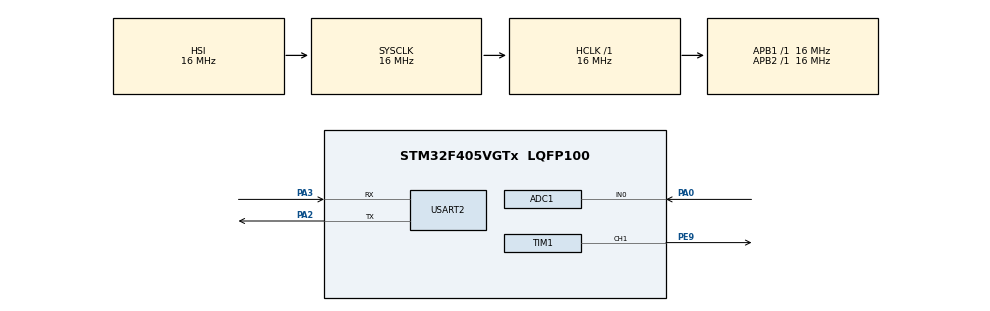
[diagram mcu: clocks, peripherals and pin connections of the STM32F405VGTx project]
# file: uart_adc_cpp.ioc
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ADC1.Channel-0\#ChannelRegularConversion=ADC_CHANNEL_0
ADC1.Channel-16\#ChannelInjectedConversion=ADC_CHANNEL_0
ADC1.Channel-17\#ChannelInjectedConversion=ADC_CHANNEL_0
ADC1.Channel-18\#ChannelInjectedConversion=ADC_CHANNEL_0
ADC1.Channel-19\#ChannelInjectedConversion=ADC_CHANNEL_0
ADC1.ContinuousConvMode=ENABLE
ADC1.DMAContinuousRequests=ENABLE
ADC1.EOCSelection=ADC_EOC_SEQ_CONV
ADC1.ExternalTrigInjecConv=ADC_EXTERNALTRIGINJECCONV_T1_TRGO
ADC1.InjNumberOfConversion=4
ADC1.InjectedOffset-16\#ChannelInjectedConversion=0
ADC1.InjectedOffset-17\#ChannelInjectedConversion=0
ADC1.InjectedOffset-18\#ChannelInjectedConversion=0
ADC1.InjectedOffset-19\#ChannelInjectedConversion=0
ADC1.InjectedRank-16\#ChannelInjectedConversion=1
ADC1.InjectedRank-17\#ChannelInjectedConversion=2
ADC1.InjectedRank-18\#ChannelInjectedConversion=3
ADC1.InjectedRank-19\#ChannelInjectedConversion=4
ADC1.NbrOfConversion=1
ADC1.NbrOfConversionFlag=1
ADC1.Rank-0\#ChannelRegularConversion=1
ADC1.Resolution=ADC_RESOLUTION_8B
ADC1.SamplingTime-0\#ChannelRegularConversion=ADC_SAMPLETIME_480CYCLES
ADC1.SamplingTime-16\#ChannelInjectedConversion=ADC_SAMPLETIME_3CYCLES
ADC1.SamplingTime-17\#ChannelInjectedConversion=ADC_SAMPLETIME_3CYCLES
ADC1.SamplingTime-18\#ChannelInjectedConversion=ADC_SAMPLETIME_3CYCLES
ADC1.SamplingTime-19\#ChannelInjectedConversion=ADC_SAMPLETIME_3CYCLES
ADC1.master=1
Dma.ADC1.1.Direction=DMA_PERIPH_TO_MEMORY
Dma.ADC1.1.FIFOMode=DMA_FIFOMODE_DISABLE
Dma.ADC1.1.Instance=DMA2_Stream0
Dma.ADC1.1.MemDataAlignment=DMA_MDATAALIGN_HALFWORD
Dma.ADC1.1.MemInc=DMA_MINC_ENABLE
Dma.ADC1.1.Mode=DMA_NORMAL
Dma.ADC1.1.PeriphDataAlignment=DMA_PDATAALIGN_HALFWORD
Dma.ADC1.1.PeriphInc=DMA_PINC_DISABLE
Dma.ADC1.1.Priority=DMA_PRIORITY_LOW
Dma.Request0=USART2_TX
Dma.Request1=ADC1
Dma.USART2_TX.0.Direction=DMA_MEMORY_TO_PERIPH
Dma.USART2_TX.0.FIFOMode=DMA_FIFOMODE_DISABLE
Dma.USART2_TX.0.Instance=DMA1_Stream6
Dma.USART2_TX.0.MemDataAlignment=DMA_MDATAALIGN_BYTE
Dma.USART2_TX.0.MemInc=DMA_MINC_ENABLE
Dma.USART2_TX.0.Mode=DMA_NORMAL
Dma.USART2_TX.0.PeriphDataAlignment=DMA_PDATAALIGN_BYTE
Dma.USART2_TX.0.PeriphInc=DMA_PINC_DISABLE
Dma.USART2_TX.0.Priority=DMA_PRIORITY_LOW
Mcu.Family=STM32F4
Mcu.Name=STM32F405VGTx
Mcu.Package=LQFP100
NVIC.DMA1_Stream6_IRQn=true\:0\:0\:false\:false\:true\:false
NVIC.DMA2_Stream0_IRQn=true\:0\:0\:false\:false\:true\:false
NVIC.PriorityGroup=NVIC_PRIORITYGROUP_4
PA0-WKUP.Signal=ADCx_IN0
PA2.Mode=Asynchronous
PA2.Signal=USART2_TX
PA3.Mode=Asynchronous
PA3.Signal=USART2_RX
PC14-OSC32_IN.Mode=LSE-External-Oscillator
PC14-OSC32_IN.Signal=RCC_OSC32_IN
PC15-OSC32_OUT.Mode=LSE-External-Oscillator
PC15-OSC32_OUT.Signal=RCC_OSC32_OUT
PE9.Signal=S_TIM1_CH1
PH0-OSC_IN.Mode=HSE-External-Oscillator
PH0-OSC_IN.Signal=RCC_OSC_IN
PH1-OSC_OUT.Mode=HSE-External-Oscillator
PH1-OSC_OUT.Signal=RCC_OSC_OUT
ProjectManager.HeapSize=0x200
ProjectManager.StackSize=0x400
ProjectManager.TargetToolchain=SW4STM32
RCC.AHBFreq_Value=16000000
RCC.APB1Freq_Value=16000000
RCC.APB2Freq_Value=16000000
RCC.CortexFreq_Value=16000000
RCC.HSE_VALUE=25000000
RCC.HSI_VALUE=16000000
RCC.SYSCLKFreq_VALUE=16000000
RCC.VCOOutputFreq_Value=192000000
SH.ADCx_IN0.0=ADC1_IN0,IN0
SH.S_TIM1_CH1.0=TIM1_CH1,Output Compare1 CH1
TIM1.Channel-Output\ Compare1\ CH1=TIM_CHANNEL_1
TIM1.Period=1000-1
TIM1.Prescaler=7200-1
TIM1.TIM_MasterOutputTrigger=TIM_TRGO_UPDATE
USART2.VirtualMode=VM_ASYNC
VP_TIM1_VS_ClockSourceITR.Mode=TriggerSource_ITR0
VP_TIM1_VS_ControllerModeClock.Mode=Clock Mode
board=custom

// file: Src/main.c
/* USER CODE BEGIN Header */
/**
 ******************************************************************************
 * @file           : main.c
 * @brief          : Main program body
 ******************************************************************************
 ** This notice applies to any and all portions of this file
 * that are not between comment pairs USER CODE BEGIN and
 * USER CODE END. Other portions of this file, whether
 * inserted by the user or by software development tools
 * are owned by their respective copyright owners.
 *
 * COPYRIGHT(c) 2019 STMicroelectronics
 *
 * Redistribution and use in source and binary forms, with or without modification,
 * are permitted provided that the following conditions are met:
 *   1. Redistributions of source code must retain the above copyright notice,
 *      this list of conditions and the following disclaimer.
 *   2. Redistributions in binary form must reproduce the above copyright notice,
 *      this list of conditions and the following disclaimer in the documentation
 *      and/or other materials provided with the distribution.
 *   3. Neither the name of STMicroelectronics nor the names of its contributors
 *      may be used to endorse or promote products derived from this software
 *      without specific prior written permission.
 *
 * THIS SOFTWARE IS PROVIDED BY THE COPYRIGHT HOLDERS AND CONTRIBUTORS "AS IS"
 * AND ANY EXPRESS OR IMPLIED WARRANTIES, INCLUDING, BUT NOT LIMITED TO, THE
 * IMPLIED WARRANTIES OF MERCHANTABILITY AND FITNESS FOR A PARTICULAR PURPOSE ARE
 * DISCLAIMED. IN NO EVENT SHALL THE COPYRIGHT HOLDER OR CONTRIBUTORS BE LIABLE
 * FOR ANY DIRECT, INDIRECT, INCIDENTAL, SPECIAL, EXEMPLARY, OR CONSEQUENTIAL
 * DAMAGES (INCLUDING, BUT NOT LIMITED TO, PROCUREMENT OF SUBSTITUTE GOODS OR
 * SERVICES; LOSS OF USE, DATA, OR PROFITS; OR BUSINESS INTERRUPTION) HOWEVER
 * CAUSED AND ON ANY THEORY OF LIABILITY, WHETHER IN CONTRACT, STRICT LIABILITY,
 * OR TORT (INCLUDING NEGLIGENCE OR OTHERWISE) ARISING IN ANY WAY OUT OF THE USE
 * OF THIS SOFTWARE, EVEN IF ADVISED OF THE POSSIBILITY OF SUCH DAMAGE.
 *
 ******************************************************************************
 */
/* USER CODE END Header */

#include "main.h"

ADC_HandleTypeDef hadc1;
DMA_HandleTypeDef hdma_adc1;

TIM_HandleTypeDef htim1;

UART_HandleTypeDef huart2;
DMA_HandleTypeDef hdma_usart2_tx;

void SystemClock_Config(void);
static void MX_GPIO_Init(void);
static void MX_DMA_Init(void);
static void MX_ADC1_Init(void);
static void MX_USART2_UART_Init(void);
static void MX_TIM1_Init(void);
/* USER CODE BEGIN PFP */

uint8_t data; //signed short pour avoir une précision suffisante pour l'affichage
float data_convertit;// une fois la valeur convertit le short et inutil
/* USER CODE END PFP */

int main(void)
{

  /* MCU Configuration--------------------------------------------------------*/

  /* Reset of all peripherals, Initializes the Flash interface and the Systick. */
  HAL_Init();

  /* Configure the system clock */
  SystemClock_Config();

  /* Initialize all configured peripherals */
  MX_GPIO_Init();
  MX_DMA_Init();
  MX_ADC1_Init();
  MX_USART2_UART_Init();
  MX_TIM1_Init();

  /* Infinite loop */
  /* USER CODE BEGIN WHILE */
	HAL_UART_Transmit(&huart2,(uint8_t*)"\033c",6,10); //reintialise la vision du  terminal à chaque reset
	//HAL_ADC_Start (&hadc1);//demarrage de l'adc
	HAL_TIM_Base_Start_IT(&htim1);
	while (1)
	{
		//conversion en continue
		HAL_ADC_Start (&hadc1);//demarrag adc
		HAL_ADC_PollForConversion(&hadc1,1000);//initialisation adc en reglant lequel ADC et combien de timout
		data = HAL_ADC_GetValue(&hadc1);//récuperation de valeur
		data_convertit =(float) (((3.3)* data)/(256-1));//conversion de la valeur en tension
		HAL_UART_Transmit(&huart2,(&data_convertit),1,10);//envoie de la valeur
		HAL_ADC_Stop (&hadc1);

		HAL_Delay(10);
		/*if(HAL_ADC_PollForConversion(&hadc1,1000000) == HAL_OK)//
		{
			data = HAL_ADC_GetValue(&hadc1);//cast int vers char pour le stockage de la donnée reçue en caractere

			//permet la conversion de la valeur en tension pour l'affiché est l'afficher directement sur l'afficheur cpp

			if(data<0)
				data_convertit = (((-3)*data)/-32768);//on prend la valeur min en tension on la multiplie par la valeur a convertir on la divise par la valeur min en signé
			else if (data > 0)
				data_convertit = (((3)*data)/32767);//on prend la valeur max en tension on la multiplie par la valeur a convertir on la divise par la valeur max en signé
			else if (data == 0 )
				data_convertit=0;//si la valeur est 0 la conversion est inutile
			HAL_UART_Transmit(&huart2,(&data_convertit),8,100);
		}*/
		//envoie de 8 octet pour la transmission d'un double ,
		//generation d'un warning car j'envoie un double au lieu d'un unsigned char
		//mais si je realise ce cast la valeur ne conviendra plus

		data = 0;//reinitialisation de la valeur
	}
    /* USER CODE END WHILE */

}

void SystemClock_Config(void)
{
  RCC_OscInitTypeDef RCC_OscInitStruct = {0};
  RCC_ClkInitTypeDef RCC_ClkInitStruct = {0};

  /**Configure the main internal regulator output voltage
  */
  __HAL_RCC_PWR_CLK_ENABLE();
  __HAL_PWR_VOLTAGESCALING_CONFIG(PWR_REGULATOR_VOLTAGE_SCALE1);
  /**Initializes the CPU, AHB and APB busses clocks
  */
  RCC_OscInitStruct.OscillatorType = RCC_OSCILLATORTYPE_HSI;
  RCC_OscInitStruct.HSIState = RCC_HSI_ON;
  RCC_OscInitStruct.HSICalibrationValue = RCC_HSICALIBRATION_DEFAULT;
  RCC_OscInitStruct.PLL.PLLState = RCC_PLL_NONE;
  if (HAL_RCC_OscConfig(&RCC_OscInitStruct) != HAL_OK)
  {
    Error_Handler();
  }
  /**Initializes the CPU, AHB and APB busses clocks
  */
  RCC_ClkInitStruct.ClockType = RCC_CLOCKTYPE_HCLK|RCC_CLOCKTYPE_SYSCLK
                              |RCC_CLOCKTYPE_PCLK1|RCC_CLOCKTYPE_PCLK2;
  RCC_ClkInitStruct.SYSCLKSource = RCC_SYSCLKSOURCE_HSI;
  RCC_ClkInitStruct.AHBCLKDivider = RCC_SYSCLK_DIV1;
  RCC_ClkInitStruct.APB1CLKDivider = RCC_HCLK_DIV1;
  RCC_ClkInitStruct.APB2CLKDivider = RCC_HCLK_DIV1;

  if (HAL_RCC_ClockConfig(&RCC_ClkInitStruct, FLASH_LATENCY_0) != HAL_OK)
  {
    Error_Handler();
  }
}

static void MX_ADC1_Init(void)
{

  ADC_ChannelConfTypeDef sConfig = {0};
  ADC_InjectionConfTypeDef sConfigInjected = {0};

  /**Configure the global features of the ADC (Clock, Resolution, Data Alignment and number of conversion)
  */
  hadc1.Instance = ADC1;
  hadc1.Init.ClockPrescaler = ADC_CLOCK_SYNC_PCLK_DIV2;
  hadc1.Init.Resolution = ADC_RESOLUTION_8B;
  hadc1.Init.ScanConvMode = ENABLE;
  hadc1.Init.ContinuousConvMode = ENABLE;
  hadc1.Init.DiscontinuousConvMode = DISABLE;
  hadc1.Init.ExternalTrigConvEdge = ADC_EXTERNALTRIGCONVEDGE_NONE;
  hadc1.Init.ExternalTrigConv = ADC_SOFTWARE_START;
  hadc1.Init.DataAlign = ADC_DATAALIGN_RIGHT;
  hadc1.Init.NbrOfConversion = 1;
  hadc1.Init.DMAContinuousRequests = ENABLE;
  hadc1.Init.EOCSelection = ADC_EOC_SEQ_CONV;
  if (HAL_ADC_Init(&hadc1) != HAL_OK)
  {
    Error_Handler();
  }
  /**Configure for the selected ADC regular channel its corresponding rank in the sequencer and its sample time.
  */
  sConfig.Channel = ADC_CHANNEL_0;
  sConfig.Rank = 1;
  sConfig.SamplingTime = ADC_SAMPLETIME_480CYCLES;
  if (HAL_ADC_ConfigChannel(&hadc1, &sConfig) != HAL_OK)
  {
    Error_Handler();
  }
  /**Configures for the selected ADC injected channel its corresponding rank in the sequencer and its sample time
  */
  sConfigInjected.InjectedChannel = ADC_CHANNEL_0;
  sConfigInjected.InjectedRank = 1;
  sConfigInjected.InjectedNbrOfConversion = 4;
  sConfigInjected.InjectedSamplingTime = ADC_SAMPLETIME_3CYCLES;
  sConfigInjected.ExternalTrigInjecConvEdge = ADC_EXTERNALTRIGINJECCONVEDGE_RISING;
  sConfigInjected.ExternalTrigInjecConv = ADC_EXTERNALTRIGINJECCONV_T1_TRGO;
  sConfigInjected.AutoInjectedConv = DISABLE;
  sConfigInjected.InjectedDiscontinuousConvMode = DISABLE;
  sConfigInjected.InjectedOffset = 0;
  if (HAL_ADCEx_InjectedConfigChannel(&hadc1, &sConfigInjected) != HAL_OK)
  {
    Error_Handler();
  }

}

static void MX_TIM1_Init(void)
{

  TIM_SlaveConfigTypeDef sSlaveConfig = {0};
  TIM_MasterConfigTypeDef sMasterConfig = {0};
  TIM_OC_InitTypeDef sConfigOC = {0};
  TIM_BreakDeadTimeConfigTypeDef sBreakDeadTimeConfig = {0};

  htim1.Instance = TIM1;
  htim1.Init.Prescaler = 7200-1;
  htim1.Init.CounterMode = TIM_COUNTERMODE_UP;
  htim1.Init.Period = 1000-1;
  htim1.Init.ClockDivision = TIM_CLOCKDIVISION_DIV1;
  htim1.Init.RepetitionCounter = 0;
  if (HAL_TIM_Base_Init(&htim1) != HAL_OK)
  {
    Error_Handler();
  }
  if (HAL_TIM_OC_Init(&htim1) != HAL_OK)
  {
    Error_Handler();
  }
  sSlaveConfig.SlaveMode = TIM_SLAVEMODE_EXTERNAL1;
  sSlaveConfig.InputTrigger = TIM_TS_ITR0;
  if (HAL_TIM_SlaveConfigSynchronization(&htim1, &sSlaveConfig) != HAL_OK)
  {
    Error_Handler();
  }
  sMasterConfig.MasterOutputTrigger = TIM_TRGO_UPDATE;
  sMasterConfig.MasterSlaveMode = TIM_MASTERSLAVEMODE_DISABLE;
  if (HAL_TIMEx_MasterConfigSynchronization(&htim1, &sMasterConfig) != HAL_OK)
  {
    Error_Handler();
  }
  sConfigOC.OCMode = TIM_OCMODE_TIMING;
  sConfigOC.Pulse = 0;
  sConfigOC.OCPolarity = TIM_OCPOLARITY_HIGH;
  sConfigOC.OCNPolarity = TIM_OCNPOLARITY_HIGH;
  sConfigOC.OCFastMode = TIM_OCFAST_DISABLE;
  sConfigOC.OCIdleState = TIM_OCIDLESTATE_RESET;
  sConfigOC.OCNIdleState = TIM_OCNIDLESTATE_RESET;
  if (HAL_TIM_OC_ConfigChannel(&htim1, &sConfigOC, TIM_CHANNEL_1) != HAL_OK)
  {
    Error_Handler();
  }
  sBreakDeadTimeConfig.OffStateRunMode = TIM_OSSR_DISABLE;
  sBreakDeadTimeConfig.OffStateIDLEMode = TIM_OSSI_DISABLE;
  sBreakDeadTimeConfig.LockLevel = TIM_LOCKLEVEL_OFF;
  sBreakDeadTimeConfig.DeadTime = 0;
  sBreakDeadTimeConfig.BreakState = TIM_BREAK_DISABLE;
  sBreakDeadTimeConfig.BreakPolarity = TIM_BREAKPOLARITY_HIGH;
  sBreakDeadTimeConfig.AutomaticOutput = TIM_AUTOMATICOUTPUT_DISABLE;
  if (HAL_TIMEx_ConfigBreakDeadTime(&htim1, &sBreakDeadTimeConfig) != HAL_OK)
  {
    Error_Handler();
  }
  HAL_TIM_MspPostInit(&htim1);

}

static void MX_USART2_UART_Init(void)
{

  huart2.Instance = USART2;
  huart2.Init.BaudRate = 115200;
  huart2.Init.WordLength = UART_WORDLENGTH_8B;
  huart2.Init.StopBits = UART_STOPBITS_1;
  huart2.Init.Parity = UART_PARITY_NONE;
  huart2.Init.Mode = UART_MODE_TX_RX;
  huart2.Init.HwFlowCtl = UART_HWCONTROL_NONE;
  huart2.Init.OverSampling = UART_OVERSAMPLING_16;
  if (HAL_UART_Init(&huart2) != HAL_OK)
  {
    Error_Handler();
  }

}

static void MX_DMA_Init(void)
{
  /* DMA controller clock enable */
  __HAL_RCC_DMA1_CLK_ENABLE();
  __HAL_RCC_DMA2_CLK_ENABLE();

  /* DMA interrupt init */
  /* DMA1_Stream6_IRQn interrupt configuration */
  HAL_NVIC_SetPriority(DMA1_Stream6_IRQn, 0, 0);
  HAL_NVIC_EnableIRQ(DMA1_Stream6_IRQn);
  /* DMA2_Stream0_IRQn interrupt configuration */
  HAL_NVIC_SetPriority(DMA2_Stream0_IRQn, 0, 0);
  HAL_NVIC_EnableIRQ(DMA2_Stream0_IRQn);

}

static void MX_GPIO_Init(void)
{

  /* GPIO Ports Clock Enable */
  __HAL_RCC_GPIOC_CLK_ENABLE();
  __HAL_RCC_GPIOH_CLK_ENABLE();
  __HAL_RCC_GPIOA_CLK_ENABLE();
  __HAL_RCC_GPIOE_CLK_ENABLE();

}

/* USER CODE BEGIN 4 */
/* USER CODE BEGIN 4 */
void HAL_ADC_ConvCpltCallback(ADC_HandleTypeDef* hadc){
	/* This is called after the conversion is completed */

}
/* USER CODE END 4 */

void Error_Handler(void)
{
}

/************************ (C) COPYRIGHT STMicroelectronics *****END OF FILE****/
